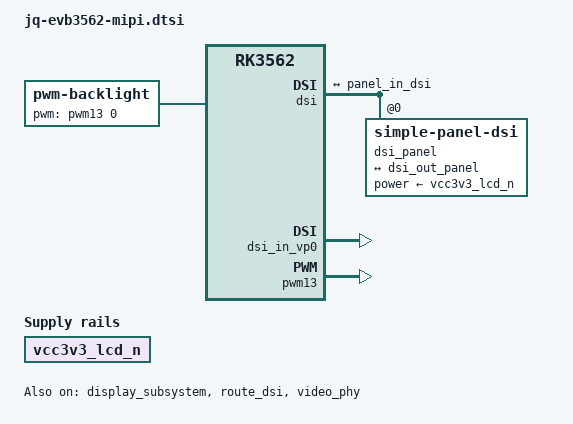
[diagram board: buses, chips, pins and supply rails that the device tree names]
// SPDX-License-Identifier: (GPL-2.0+ OR MIT)
/*
 * Copyright (c) 2022 Rockchip Electronics Co., Ltd.
 *
 */

#include <dt-bindings/display/drm_mipi_dsi.h>
#include <dt-bindings/gpio/gpio.h>
#include <dt-bindings/pinctrl/rockchip.h>

#include "rk3562.dtsi"
#include "rk3562-linux.dtsi"
#include "rk3562-rk809.dtsi"
#include <dt-bindings/sensor-dev.h>
#include <dt-bindings/input/input.h>


/ {
	backlight: backlight {
		compatible = "pwm-backlight";
		//pwms = <&pwm4 0 25000 0>;
		pwms = <&pwm13 0 25000 0>;
		brightness-levels = <
			  0  20  20  21  21  22  22  23
			 23  24  24  25  25  26  26  27
			 27  28  28  29  29  30  30  31
			 31  32  32  33  33  34  34  35
			 35  36  36  37  37  38  38  39
			 40  41  42  43  44  45  46  47
			 48  49  50  51  52  53  54  55
			 56  57  58  59  60  61  62  63
			 64  65  66  67  68  69  70  71
			 72  73  74  75  76  77  78  79
			 80  81  82  83  84  85  86  87
			 88  89  90  91  92  93  94  95
			 96  97  98  99 100 101 102 103
			104 105 106 107 108 109 110 111
			112 113 114 115 116 117 118 119
			120 121 122 123 124 125 126 127
			128 129 130 131 132 133 134 135
			136 137 138 139 140 141 142 143
			144 145 146 147 148 149 150 151
			152 153 154 155 156 157 158 159
			160 161 162 163 164 165 166 167
			168 169 170 171 172 173 174 175
			176 177 178 179 180 181 182 183
			184 185 186 187 188 189 190 191
			192 193 194 195 196 197 198 199
			200 201 202 203 204 205 206 207
			208 209 210 211 212 213 214 215
			216 217 218 219 220 221 222 223
			224 225 226 227 228 229 230 231
			232 233 234 235 236 237 238 239
			240 241 242 243 244 245 246 247
			248 249 250 251 252 253 254 255
		>;
		default-brightness-level = <200>;
	};

	vcc3v3_lcd_n: vcc3v3-lcd0-n {
		compatible = "regulator-fixed";
		regulator-name = "vcc3v3_lcd_n";
		regulator-boot-on;
		regulator-state-mem {
			regulator-off-in-suspend;
		};
	};
};

&display_subsystem {
	status = "okay";
};

&dsi {
	status = "okay";
	//rockchip,lane-rate = <1454>;
	dsi_panel: panel@0 {
		status = "okay";
		compatible = "simple-panel-dsi";
		reg = <0>;
		power-supply = <&vcc3v3_lcd_n>;
		pinctrl-names = "default";
		// pinctrl-0 = <&lcd_rst_gpio>;
		//reset-gpios = <&gpio3 RK_PA0 GPIO_ACTIVE_LOW>;
//		reset-gpios = <&gpio3 RK_PA0 GPIO_ACTIVE_LOW>;
		
//		backlight = <&backlight>;
		reset-delay-ms = <60>;
		enable-delay-ms = <60>;
		prepare-delay-ms = <60>;
		unprepare-delay-ms = <60>;
		disable-delay-ms = <60>;
		init-delay-ms = <60>;
/*
		reset-delay-ms = <10>;
		enable-delay-ms = <100>;
		prepare-delay-ms = <100>;
		unprepare-delay-ms = <20>;
		disable-delay-ms = <50>;
*/

		dsi,flags = <(MIPI_DSI_MODE_VIDEO | MIPI_DSI_MODE_VIDEO_BURST |
			MIPI_DSI_MODE_LPM | MIPI_DSI_MODE_EOT_PACKET)>;




//		dsi,flags = <(MIPI_DSI_MODE_VIDEO | MIPI_DSI_MODE_VIDEO_BURST | MIPI_DSI_MODE_VIDEO_NO_HBP | 
//			MIPI_DSI_MODE_LPM | MIPI_DSI_MODE_NO_EOT_PACKET)>;
		dsi,format = <MIPI_DSI_FMT_RGB888>;
		dsi,lanes  = <4>;
		
		panel-init-sequence = [
			
			39 00 04 FF 98 81 03
			15 00 02 01 00
			15 00 02 02 00
			15 00 02 03 53
			15 00 02 04 00
			15 00 02 05 00
			15 00 02 06 08
			15 00 02 07 00
			15 00 02 08 00
			15 00 02 09 00
			15 00 02 0a 00
			15 00 02 0b 00
			15 00 02 0c 00
			15 00 02 0d 00
			15 00 02 0e 00
			15 00 02 0f 26
			15 00 02 10 26
			15 00 02 11 00
			15 00 02 12 00
			15 00 02 13 00
			15 00 02 14 00
			15 00 02 15 00
			15 00 02 16 00
			15 00 02 17 00
			15 00 02 18 00
			15 00 02 19 00
			15 00 02 1a 00
			15 00 02 1b 00
			
			
			39 00 04 FF 98 81 01
			/* 时钟和电源设置 */
			15 00 02 1C 00
			15 00 02 1D 00
			15 00 02 1E 40 /* CLKA 40 */
			15 00 02 1F C0
			15 00 02 20 06
			15 00 02 21 01
			15 00 02 22 07
			15 00 02 23 00
			15 00 02 24 8A
			15 00 02 25 8A
			15 00 02 26 00
			15 00 02 27 00
			15 00 02 28 33
			15 00 02 29 33
			15 00 02 2A 00
			15 00 02 2B 00
			15 00 02 2C 08
			15 00 02 2D 08
			15 00 02 2E 0B
			15 00 02 2F 0B
			15 00 02 30 00
			15 00 02 31 00
			15 00 02 32 42
			15 00 02 33 00
			15 00 02 34 00
			15 00 02 35 0A
			15 00 02 36 00
			15 00 02 37 08
			15 00 02 38 3C
			15 00 02 39 00
			15 00 02 3A 00
			15 00 02 3B 00
			15 00 02 3C 00
			15 00 02 3D 00
			15 00 02 3E 00
			15 00 02 3F 00
			15 00 02 40 00
			15 00 02 41 00
			15 00 02 42 00
			15 00 02 43 08
			15 00 02 44 00
			/* GIP_2设置 */
			15 00 02 50 01
			15 00 02 51 23
			15 00 02 52 45
			15 00 02 53 67
			15 00 02 54 89
			15 00 02 55 AB
			15 00 02 56 01
			15 00 02 57 23
			15 00 02 58 45
			15 00 02 59 67
			15 00 02 5A 89
			15 00 02 5B AB
			15 00 02 5C CD
			15 00 02 5D EF
			
			
			/* 正极性Gamma */
			15 00 02 A0 00
			15 00 02 A1 1B
			15 00 02 A2 2A
			15 00 02 A3 14
			15 00 02 A4 17
			15 00 02 A5 2B
			15 00 02 A6 1F
			15 00 02 A7 20
			15 00 02 A8 93
			15 00 02 A9 1E
			15 00 02 AA 2A
			15 00 02 AB 7E
			15 00 02 AC 1B
			15 00 02 AD 19
			15 00 02 AE 4C
			15 00 02 AF 22
			15 00 02 B0 28
			/* 负极性Gamma */
			15 00 02 C0 00
			15 00 02 C1 1B
			15 00 02 C2 2A
			15 00 02 C3 14
			15 00 02 C4 17
			15 00 02 C5 2B
			15 00 02 C6 1F
			15 00 02 C7 20
			15 00 02 C8 93
			15 00 02 C9 1E
			15 00 02 CA 2A
			15 00 02 CB 7E
			15 00 02 CC 1B
			15 00 02 CD 19
			15 00 02 CE 4C
			15 00 02 CF 22
			15 00 02 D0 28
			15 00 02 D1 4B
			15 00 02 D2 59
			15 00 02 D3 23
			
			
			39 00 04 FF 98 81 04
			15 00 02 6E 2B /* VGH 15V */
			15 00 02 6F 35 /* VGL设置 */
			15 00 02 3A A4 /* Power Saving */
			15 00 02 8D 1A /* VGL -11V */
			15 00 02 87 BA /* ESD */
			15 00 02 B2 D1
			15 00 02 88 0B
			15 00 02 38 01
			15 00 02 39 00
			15 00 02 B5 07 /* Gamma Bias */
			15 00 02 31 75
			
			
			39 00 04 FF 98 81 00
			/* 开机序列 */
			15 00 02 11 00 /* Sleep Out */
			05 78 00 /* 延时120ms */
			15 00 02 29 00 /* Display On */
			15 00 02 35 00 /* TE Setting */
			05 78 01 11
			05 14 01 29
		];


		panel-exit-sequence = [
			05 00 01 28    /* Display Off */
			05 00 01 10    /* Sleep In */
		];



		disp_timings0: display-timings { 
			native-mode = <&dsi_timing0>;
			dsi_timing0: timing0 {
				clock-frequency = <67000000>;
				hactive = <800>;
				vactive = <1280>;
				hfront-porch = <20>;
				hback-porch = <20>;
				hsync-len = <6>;
				vfront-porch = <30>;
				vback-porch = <8>;
				vsync-len = <4>;
				hsync-active = <0>;
				vsync-active = <0>;
				de-active = <0>;
				pixelclk-active = <0>;

			};
		};

		ports {
			#address-cells = <1>;
			#size-cells = <0>;

			port@0 {
				reg = <0>;
				panel_in_dsi: endpoint {
					remote-endpoint = <&dsi_out_panel>;
				};
			};
		};
	};

	ports {
		#address-cells = <1>;
		#size-cells = <0>;

		port@1 {
			reg = <1>;
			dsi_out_panel: endpoint {
				remote-endpoint = <&panel_in_dsi>;
			};
		};
	};
};

&display_subsystem {
        status = "okay";
};

&route_dsi {
	status = "okay";
};

&dsi_in_vp0 {
	status = "okay";
};

&video_phy {
	status = "okay";
};

/*
&pwm4 {
	pinctrl-0 = <&pwm4m0_pins>;
	status = "okay";
};*/

&pwm13 {
        pinctrl-0 = <&pwm13m1_pins>;
        status = "okay";
};






&pinctrl {



};

